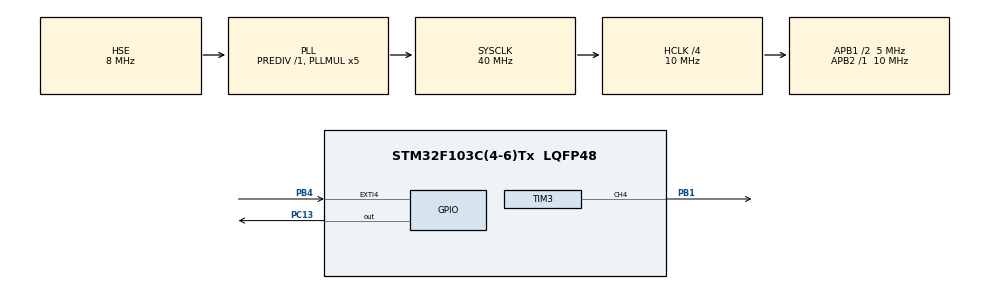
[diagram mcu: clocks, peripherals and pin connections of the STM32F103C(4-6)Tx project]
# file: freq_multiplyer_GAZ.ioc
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Mcu.Family=STM32F1
Mcu.Name=STM32F103C(4-6)Tx
Mcu.Package=LQFP48
NVIC.EXTI4_IRQn=true\:5\:0\:true\:false\:true\:true\:true\:true
NVIC.PriorityGroup=NVIC_PRIORITYGROUP_4
NVIC.TIM2_IRQn=true\:5\:0\:true\:false\:true\:true\:true\:true
PA13.Mode=Trace_Asynchronous_SW
PA13.Signal=SYS_JTMS-SWDIO
PA14.Mode=Trace_Asynchronous_SW
PA14.Signal=SYS_JTCK-SWCLK
PB1.Signal=S_TIM3_CH4
PB3.Mode=Trace_Asynchronous_SW
PB3.Signal=SYS_JTDO-TRACESWO
PB4.Signal=GPXTI4
PC13-TAMPER-RTC.GPIO_ModeDefaultOutputPP=GPIO_MODE_OUTPUT_OD
PC13-TAMPER-RTC.GPIO_PuPd=GPIO_NOPULL
PC13-TAMPER-RTC.Signal=GPIO_Output
PD0-OSC_IN.Mode=HSE-External-Oscillator
PD0-OSC_IN.Signal=RCC_OSC_IN
PD1-OSC_OUT.Mode=HSE-External-Oscillator
PD1-OSC_OUT.Signal=RCC_OSC_OUT
ProjectManager.HeapSize=0x200
ProjectManager.StackSize=0x400
ProjectManager.TargetToolchain=EWARM V8.32
RCC.AHBCLKDivider=RCC_SYSCLK_DIV4
RCC.AHBFreq_Value=10000000
RCC.APB1CLKDivider=RCC_HCLK_DIV2
RCC.APB1Freq_Value=5000000
RCC.APB1TimFreq_Value=10000000
RCC.APB2Freq_Value=10000000
RCC.APB2TimFreq_Value=10000000
RCC.HCLKFreq_Value=10000000
RCC.PLLMUL=RCC_PLL_MUL5
RCC.PLLSourceVirtual=RCC_PLLSOURCE_HSE
RCC.SYSCLKFreq_VALUE=40000000
RCC.SYSCLKSource=RCC_SYSCLKSOURCE_PLLCLK
RCC.USBFreq_Value=40000000
SH.S_TIM3_CH4.0=TIM3_CH4,PWM Generation4 CH4
TIM2.Prescaler=99
TIM3.AutoReloadPreload=TIM_AUTORELOAD_PRELOAD_ENABLE
TIM3.Channel-PWM\ Generation4\ CH4=TIM_CHANNEL_4
TIM3.Prescaler=99
VP_TIM2_VS_ClockSourceINT.Mode=Internal
board=custom

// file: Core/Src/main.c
/* USER CODE BEGIN Header */
/**
  ******************************************************************************
  * @file           : main.c
  * @brief          : Main program body
  ******************************************************************************
  * @attention
  *
  * Copyright (c) 2025 STMicroelectronics.
  * All rights reserved.
  *
  * This software is licensed under terms that can be found in the LICENSE file
  * in the root directory of this software component.
  * If no LICENSE file comes with this software, it is provided AS-IS.
  *
  ******************************************************************************
  */
/* USER CODE END Header */
#include "main.h"
#include "tim.h"
#include "gpio.h"

/* USER CODE BEGIN Includes */
volatile uint16_t current_tim=65535;
extern TIM_HandleTypeDef htim2;
extern TIM_HandleTypeDef htim3;
/* USER CODE END Includes */

void SystemClock_Config(void);

int main(void)
{

  /* MCU Configuration--------------------------------------------------------*/

  /* Reset of all peripherals, Initializes the Flash interface and the Systick. */
  HAL_Init();

  /* Configure the system clock */
  SystemClock_Config();

  /* Initialize all configured peripherals */
  MX_GPIO_Init();
  MX_TIM3_Init();
  MX_TIM2_Init();
  /* USER CODE BEGIN 2 */
  HAL_TIM_Base_Start_IT(&htim2);
  TIM3->ARR=60000;
  TIM3->CCR4=60001;
  HAL_TIM_PWM_Start(&htim3,TIM_CHANNEL_4);
  /* USER CODE END 2 */

  /* Infinite loop */
  /* USER CODE BEGIN WHILE */
  uint16_t temp;
  while (1)
  {
    /* USER CODE END WHILE */

    /* USER CODE BEGIN 3 */
    if ((current_tim > 60000)||(current_tim<10))
    {
      TIM3->ARR=60000;
      TIM3->CCR4=60001;
    }else{
      temp=current_tim / 1.625;
      TIM3->ARR=temp;
      TIM3->CCR4=temp/2;
      HAL_GPIO_TogglePin(GPIOC,GPIO_PIN_13);
    }
    HAL_Delay(2);

  }
  /* USER CODE END 3 */
}

void SystemClock_Config(void)
{
  RCC_OscInitTypeDef RCC_OscInitStruct = {0};
  RCC_ClkInitTypeDef RCC_ClkInitStruct = {0};

  /** Initializes the RCC Oscillators according to the specified parameters
  * in the RCC_OscInitTypeDef structure.
  */
  RCC_OscInitStruct.OscillatorType = RCC_OSCILLATORTYPE_HSE;
  RCC_OscInitStruct.HSEState = RCC_HSE_ON;
  RCC_OscInitStruct.HSEPredivValue = RCC_HSE_PREDIV_DIV1;
  RCC_OscInitStruct.HSIState = RCC_HSI_ON;
  RCC_OscInitStruct.PLL.PLLState = RCC_PLL_ON;
  RCC_OscInitStruct.PLL.PLLSource = RCC_PLLSOURCE_HSE;
  RCC_OscInitStruct.PLL.PLLMUL = RCC_PLL_MUL5;
  if (HAL_RCC_OscConfig(&RCC_OscInitStruct) != HAL_OK)
  {
    Error_Handler();
  }

  /** Initializes the CPU, AHB and APB buses clocks
  */
  RCC_ClkInitStruct.ClockType = RCC_CLOCKTYPE_HCLK|RCC_CLOCKTYPE_SYSCLK
                              |RCC_CLOCKTYPE_PCLK1|RCC_CLOCKTYPE_PCLK2;
  RCC_ClkInitStruct.SYSCLKSource = RCC_SYSCLKSOURCE_PLLCLK;
  RCC_ClkInitStruct.AHBCLKDivider = RCC_SYSCLK_DIV4;
  RCC_ClkInitStruct.APB1CLKDivider = RCC_HCLK_DIV2;
  RCC_ClkInitStruct.APB2CLKDivider = RCC_HCLK_DIV1;

  if (HAL_RCC_ClockConfig(&RCC_ClkInitStruct, FLASH_LATENCY_1) != HAL_OK)
  {
    Error_Handler();
  }
}

void Error_Handler(void)
{
  __disable_irq();
  while (1)
  {
  }
}
